# ESP32-S3 register map
Vendor: ESPRESSIF SYSTEMS (SHANGHAI) CO., LTD.; Series: ESP32 S-Series; File version: 22
CPU: Xtensa LX7 r0p0, little endian, no MPU, FPU, 0 interrupt priority bits
Address unit: 32 bits
Registers are 32-bit, read-write, reset 0x0 unless marked. A register's access mark holds for its fields unless they carry their own. Offsets are from the block's base; [hi:lo] are bit positions.

## RTC_I2C — Low-power I2C (Inter-Integrated Circuit) Controller
Base 0x60008C00
0x00 SCL_LOW reset 0x100 — configure low scl period
  [19:0] PERIOD — time period that scl =0
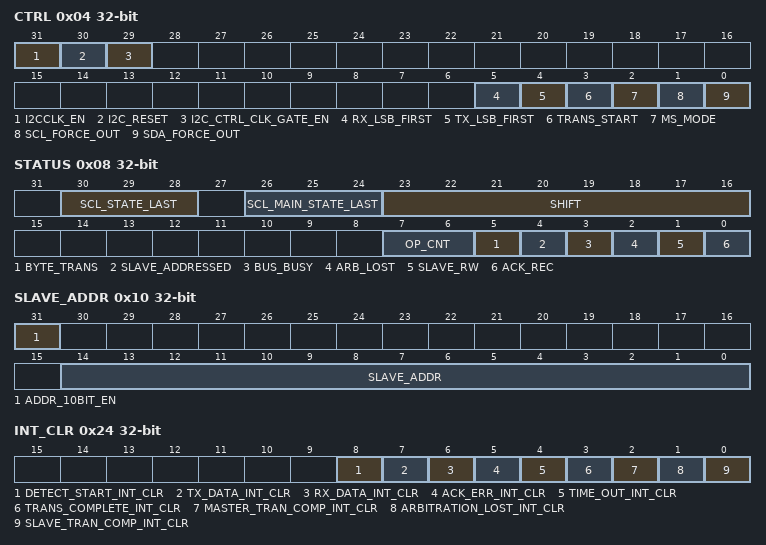
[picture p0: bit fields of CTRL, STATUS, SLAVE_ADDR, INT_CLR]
0x04 CTRL — configure i2c ctrl
  [31] I2CCLK_EN — rtc i2c reg clk gating
  [30] I2C_RESET — rtc i2c sw reset
  [29] I2C_CTRL_CLK_GATE_EN — configure i2c ctrl clk enable
  [5] RX_LSB_FIRST — receive lsb first
  [4] TX_LSB_FIRST — transit lsb first
  [3] TRANS_START — force start
  [2] MS_MODE — 1=master,0=slave
  [1] SCL_FORCE_OUT — 1=push pull,0=open drain
  [0] SDA_FORCE_OUT — 1=push pull,0=open drain
0x08 STATUS ro — get i2c status
  [30:28] SCL_STATE_LAST — scl last status
  [26:24] SCL_MAIN_STATE_LAST — i2c last main status
  [23:16] SHIFT — shifter content
  [7:6] OP_CNT — which operation is working
  [5] BYTE_TRANS — One byte transit done
  [4] SLAVE_ADDRESSED — slave reg sub address
  [3] BUS_BUSY — bus is busy
  [2] ARB_LOST — arbitration is lost
  [1] SLAVE_RW — slave read or write
  [0] ACK_REC — ack response
0x0C TO reset 0x10000 — configure time out
  [19:0] TIME_OUT — time out threshold
0x10 SLAVE_ADDR — configure slave id
  [31] ADDR_10BIT_EN — i2c 10bit mode enable
  [14:0] SLAVE_ADDR — slave address
0x14 SCL_HIGH reset 0x100 — configure high scl period
  [19:0] PERIOD — time period that scl = 1
0x18 SDA_DUTY reset 0x10 — configure sda duty
  [19:0] NUM — time period for SDA to toggle after SCL goes low
0x1C SCL_START_PERIOD reset 0x8 — configure scl start period
  [19:0] SCL_START_PERIOD — time period for SCL to toggle after I2C start is triggered
0x20 SCL_STOP_PERIOD reset 0x8 — configure scl stop period
  [19:0] SCL_STOP_PERIOD — time period for SCL to stop after I2C end is triggered
0x24 INT_CLR wo — interrupt clear register
  [8] DETECT_START_INT_CLR — clear detect start interrupt
  [7] TX_DATA_INT_CLR — clear transit load data complete interrupt
  [6] RX_DATA_INT_CLR — clear receive data interrupt
  [5] ACK_ERR_INT_CLR — clear ack error interrupt
  [4] TIME_OUT_INT_CLR — clear time out interrupt
  [3] TRANS_COMPLETE_INT_CLR — clear transit complete interrupt
  [2] MASTER_TRAN_COMP_INT_CLR — clear master transit complete interrupt
  [1] ARBITRATION_LOST_INT_CLR — clear arbitration lost interrupt
  [0] SLAVE_TRAN_COMP_INT_CLR — clear slave transit complete interrupt
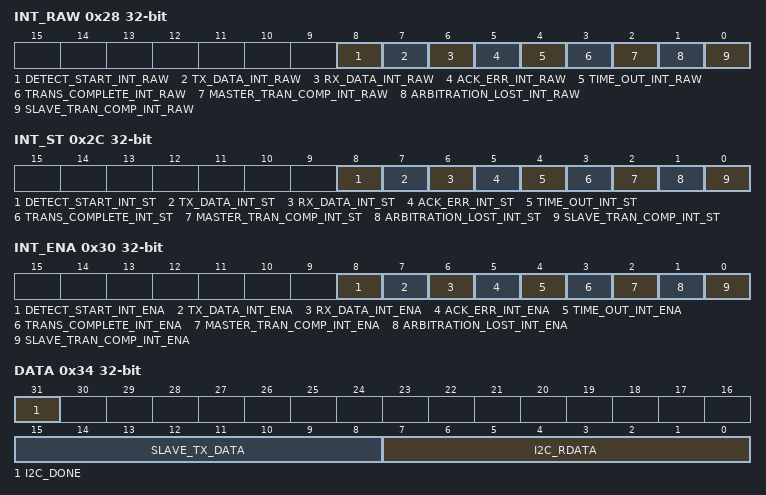
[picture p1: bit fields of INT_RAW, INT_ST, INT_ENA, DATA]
0x28 INT_RAW ro — interrupt raw register
  [8] DETECT_START_INT_RAW — detect start interrupt raw
  [7] TX_DATA_INT_RAW — transit data interrupt raw
  [6] RX_DATA_INT_RAW — receive data interrupt raw
  [5] ACK_ERR_INT_RAW — ack error interrupt raw
  [4] TIME_OUT_INT_RAW — time out interrupt raw
  [3] TRANS_COMPLETE_INT_RAW — transit complete interrupt raw
  [2] MASTER_TRAN_COMP_INT_RAW — master transit complete interrupt raw
  [1] ARBITRATION_LOST_INT_RAW — arbitration lost interrupt raw
  [0] SLAVE_TRAN_COMP_INT_RAW — slave transit complete interrupt raw
0x2C INT_ST ro — interrupt state register
  [8] DETECT_START_INT_ST — detect start interrupt state
  [7] TX_DATA_INT_ST — transit data interrupt state
  [6] RX_DATA_INT_ST — receive data interrupt state
  [5] ACK_ERR_INT_ST — ack error interrupt state
  [4] TIME_OUT_INT_ST — time out interrupt state
  [3] TRANS_COMPLETE_INT_ST — transit complete interrupt state
  [2] MASTER_TRAN_COMP_INT_ST — master transit complete interrupt state
  [1] ARBITRATION_LOST_INT_ST — arbitration lost interrupt state
  [0] SLAVE_TRAN_COMP_INT_ST — slave transit complete interrupt state
0x30 INT_ENA — interrupt enable register
  [8] DETECT_START_INT_ENA — enable detect start interrupt
  [7] TX_DATA_INT_ENA — enable transit data interrupt
  [6] RX_DATA_INT_ENA — enable receive data interrupt
  [5] ACK_ERR_INT_ENA — enable eack error interrupt
  [4] TIME_OUT_INT_ENA — enable time out interrupt
  [3] TRANS_COMPLETE_INT_ENA — enable transit complete interrupt
  [2] MASTER_TRAN_COMP_INT_ENA — enable master transit complete interrupt
  [1] ARBITRATION_LOST_INT_ENA — enable arbitration lost interrupt
  [0] SLAVE_TRAN_COMP_INT_ENA — enable slave transit complete interrupt
0x34 DATA access per field — get i2c data status
  [31] I2C_DONE ro
  [15:8] SLAVE_TX_DATA rw — data sent by slave
  [7:0] I2C_RDATA ro — data received
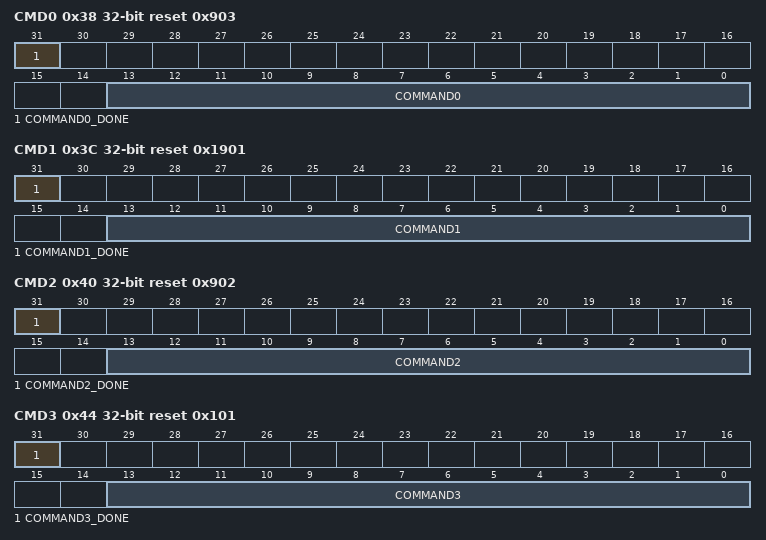
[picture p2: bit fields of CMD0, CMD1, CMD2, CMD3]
0x38 CMD0 access per field reset 0x903 — i2c commond0 register
  [31] COMMAND0_DONE ro, [13:0] COMMAND0 rw
0x3C CMD1 access per field reset 0x1901 — i2c commond1 register
  [31] COMMAND1_DONE ro, [13:0] COMMAND1 rw
0x40 CMD2 access per field reset 0x902 — i2c commond2 register
  [31] COMMAND2_DONE ro, [13:0] COMMAND2 rw
0x44 CMD3 access per field reset 0x101 — i2c commond3 register
  [31] COMMAND3_DONE ro, [13:0] COMMAND3 rw
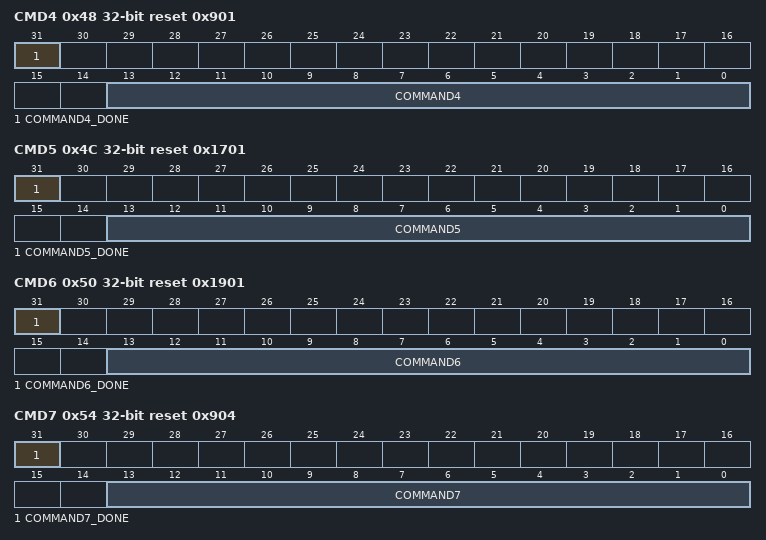
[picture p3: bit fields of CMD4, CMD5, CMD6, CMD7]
0x48 CMD4 access per field reset 0x901 — i2c commond4 register
  [31] COMMAND4_DONE ro, [13:0] COMMAND4 rw
0x4C CMD5 access per field reset 0x1701 — i2c commond5_register
  [31] COMMAND5_DONE ro, [13:0] COMMAND5 rw
0x50 CMD6 access per field reset 0x1901 — i2c commond6 register
  [31] COMMAND6_DONE ro, [13:0] COMMAND6 rw
0x54 CMD7 access per field reset 0x904 — i2c commond7 register
  [31] COMMAND7_DONE ro, [13:0] COMMAND7 rw
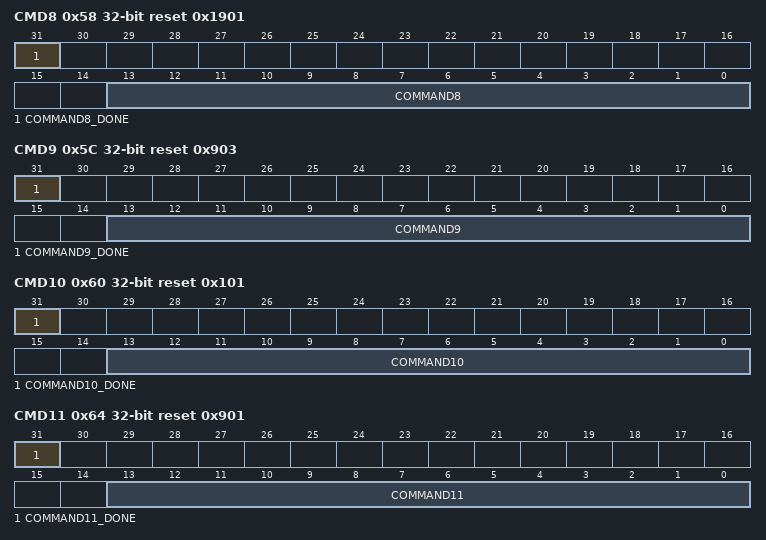
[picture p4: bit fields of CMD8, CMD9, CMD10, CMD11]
0x58 CMD8 access per field reset 0x1901 — i2c commond8 register
  [31] COMMAND8_DONE ro, [13:0] COMMAND8 rw
0x5C CMD9 access per field reset 0x903 — i2c commond9 register
  [31] COMMAND9_DONE ro, [13:0] COMMAND9 rw
0x60 CMD10 access per field reset 0x101 — i2c commond10 register
  [31] COMMAND10_DONE ro, [13:0] COMMAND10 rw
0x64 CMD11 access per field reset 0x901 — i2c commond11 register
  [31] COMMAND11_DONE ro, [13:0] COMMAND11 rw
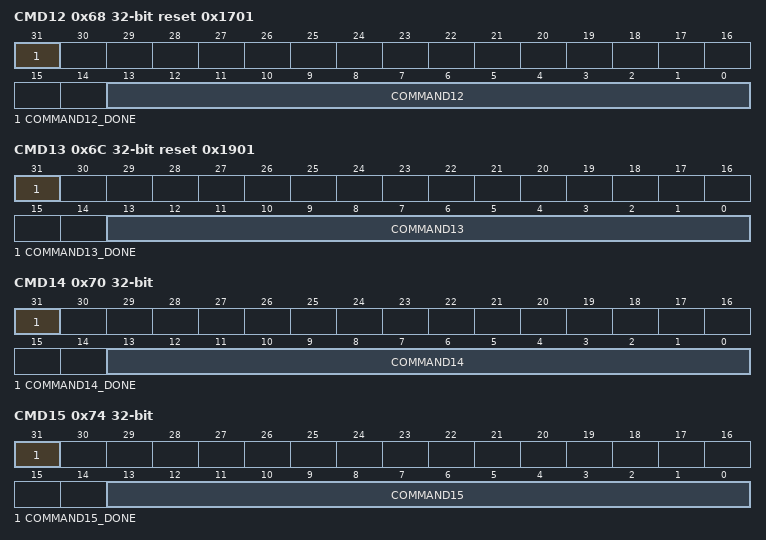
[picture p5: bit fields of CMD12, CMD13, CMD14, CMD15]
0x68 CMD12 access per field reset 0x1701 — i2c commond12 register
  [31] COMMAND12_DONE ro, [13:0] COMMAND12 rw
0x6C CMD13 access per field reset 0x1901 — i2c commond13 register
  [31] COMMAND13_DONE ro, [13:0] COMMAND13 rw
0x70 CMD14 access per field — i2c commond14 register
  [31] COMMAND14_DONE ro, [13:0] COMMAND14 rw
0x74 CMD15 access per field — i2c commond15 register
  [31] COMMAND15_DONE ro, [13:0] COMMAND15 rw
0xFC DATE reset 0x1905310 — version register
  [27:0] I2C_DATE — version
